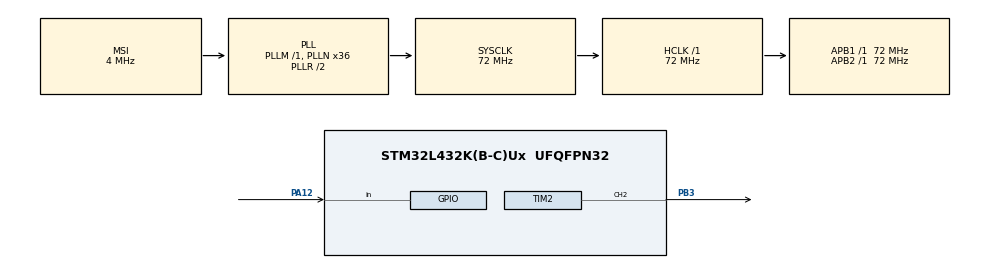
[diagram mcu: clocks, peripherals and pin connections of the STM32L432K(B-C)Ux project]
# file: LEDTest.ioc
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Mcu.Family=STM32L4
Mcu.Name=STM32L432K(B-C)Ux
Mcu.Package=UFQFPN32
NVIC.PriorityGroup=NVIC_PRIORITYGROUP_4
PA0.GPIO_Label=MCO [High speed clock in]
PA0.Mode=HSE-External-Clock-Source-for-LittleOrca
PA0.Signal=RCC_CK_IN
PA12.Signal=GPIO_Input
PA13\ (JTMS-SWDIO).GPIO_Label=SWDIO
PA13\ (JTMS-SWDIO).Mode=Serial_Wire
PA13\ (JTMS-SWDIO).Signal=SYS_JTMS-SWDIO
PA14\ (JTCK-SWCLK).GPIO_Label=SWCLK
PA14\ (JTCK-SWCLK).Mode=Serial_Wire
PA14\ (JTCK-SWCLK).Signal=SYS_JTCK-SWCLK
PA15\ (JTDI).Signal=USART2_RX
PA2.GPIO_Label=VCP_TX
PA2.Signal=USART2_TX
PB3\ (JTDO-TRACESWO).Signal=S_TIM2_CH2
PC14-OSC32_IN\ (PC14).Mode=LSE-External-Oscillator
PC14-OSC32_IN\ (PC14).Signal=RCC_OSC32_IN
PC15-OSC32_OUT\ (PC15).Mode=LSE-External-Oscillator
PC15-OSC32_OUT\ (PC15).Signal=RCC_OSC32_OUT
ProjectManager.HeapSize=0x200
ProjectManager.StackSize=0x400
ProjectManager.TargetToolchain=STM32CubeIDE
RCC.AHBFreq_Value=72000000
RCC.APB1Freq_Value=72000000
RCC.APB1TimFreq_Value=72000000
RCC.APB2Freq_Value=72000000
RCC.APB2TimFreq_Value=72000000
RCC.CortexFreq_Value=72000000
RCC.HCLKFreq_Value=72000000
RCC.HSE_VALUE=8000000
RCC.HSI16_VALUE=16000000
RCC.HSI48_VALUE=48000000
RCC.HSI_VALUE=16000000
RCC.MSI_VALUE=4000000
RCC.PLLMUL=RCC_PLLMUL_4
RCC.PLLN=36
RCC.SYSCLKFreq_VALUE=72000000
RCC.SYSCLKSource=RCC_SYSCLKSOURCE_PLLCLK
RCC.VCOOutputFreq_Value=144000000
SH.S_TIM2_CH2.0=TIM2_CH2,PWM Generation2 CH2
TIM2.AutoReloadPreload=TIM_AUTORELOAD_PRELOAD_ENABLE
TIM2.Channel-PWM\ Generation2\ CH2=TIM_CHANNEL_2
TIM2.Period=65535
VP_TIM2_VS_ClockSourceINT.Mode=Internal
board=NUCLEO-L432KC

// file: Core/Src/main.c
/* USER CODE BEGIN Header */
/**
  ******************************************************************************
  * @file           : main.c
  * @brief          : Main program body
  ******************************************************************************
  * @attention
  *
  * Copyright (c) 2022 STMicroelectronics.
  * All rights reserved.
  *
  * This software is licensed under terms that can be found in the LICENSE file
  * in the root directory of this software component.
  * If no LICENSE file comes with this software, it is provided AS-IS.
  *
  ******************************************************************************
  */
/* USER CODE END Header */
#include "main.h"

 TIM_HandleTypeDef htim2;

void SystemClock_Config(void);
static void MX_GPIO_Init(void);
static void MX_TIM2_Init(void);

int main(void)
{
  /* USER CODE BEGIN 1 */
	int32_t CH2_DC = 0;
	int32_t delay = 1;

  /* USER CODE END 1 */

  /* MCU Configuration--------------------------------------------------------*/

  /* Reset of all peripherals, Initializes the Flash interface and the Systick. */
  HAL_Init();

  /* Configure the system clock */
  SystemClock_Config();

  /* Initialize all configured peripherals */
  MX_GPIO_Init();
  MX_TIM2_Init();
  /* USER CODE BEGIN 2 */

  HAL_TIM_PWM_Start(&htim2, TIM_CHANNEL_2); //Starts PWM

  /* USER CODE END 2 */

  /* Infinite loop */
  /* USER CODE BEGIN WHILE */
  while (1)
  {
	  while(CH2_DC < 65535){
		  TIM2->CCR2 = CH2_DC;
		  CH2_DC += 70;
		  HAL_Delay(delay);
	  }
	  while(CH2_DC > 0){
		  TIM2->CCR2 = CH2_DC;
		  CH2_DC -= 70;
		  //HAL_GPIO_WritePin(GPIOB, GPIO_PIN_3, 0);
		  HAL_Delay(delay);
	  }
    /* USER CODE END WHILE */

  }
}

void SystemClock_Config(void)
{
  RCC_OscInitTypeDef RCC_OscInitStruct = {0};
  RCC_ClkInitTypeDef RCC_ClkInitStruct = {0};

  /** Configure the main internal regulator output voltage
  */
  if (HAL_PWREx_ControlVoltageScaling(PWR_REGULATOR_VOLTAGE_SCALE1) != HAL_OK)
  {
    Error_Handler();
  }

  /** Configure LSE Drive Capability
  */
  HAL_PWR_EnableBkUpAccess();
  __HAL_RCC_LSEDRIVE_CONFIG(RCC_LSEDRIVE_LOW);

  /** Initializes the RCC Oscillators according to the specified parameters
  * in the RCC_OscInitTypeDef structure.
  */
  RCC_OscInitStruct.OscillatorType = RCC_OSCILLATORTYPE_LSE|RCC_OSCILLATORTYPE_MSI;
  RCC_OscInitStruct.LSEState = RCC_LSE_ON;
  RCC_OscInitStruct.MSIState = RCC_MSI_ON;
  RCC_OscInitStruct.MSICalibrationValue = 0;
  RCC_OscInitStruct.MSIClockRange = RCC_MSIRANGE_6;
  RCC_OscInitStruct.PLL.PLLState = RCC_PLL_ON;
  RCC_OscInitStruct.PLL.PLLSource = RCC_PLLSOURCE_MSI;
  RCC_OscInitStruct.PLL.PLLM = 1;
  RCC_OscInitStruct.PLL.PLLN = 36;
  RCC_OscInitStruct.PLL.PLLP = RCC_PLLP_DIV7;
  RCC_OscInitStruct.PLL.PLLQ = RCC_PLLQ_DIV2;
  RCC_OscInitStruct.PLL.PLLR = RCC_PLLR_DIV2;
  if (HAL_RCC_OscConfig(&RCC_OscInitStruct) != HAL_OK)
  {
    Error_Handler();
  }

  /** Initializes the CPU, AHB and APB buses clocks
  */
  RCC_ClkInitStruct.ClockType = RCC_CLOCKTYPE_HCLK|RCC_CLOCKTYPE_SYSCLK
                              |RCC_CLOCKTYPE_PCLK1|RCC_CLOCKTYPE_PCLK2;
  RCC_ClkInitStruct.SYSCLKSource = RCC_SYSCLKSOURCE_PLLCLK;
  RCC_ClkInitStruct.AHBCLKDivider = RCC_SYSCLK_DIV1;
  RCC_ClkInitStruct.APB1CLKDivider = RCC_HCLK_DIV1;
  RCC_ClkInitStruct.APB2CLKDivider = RCC_HCLK_DIV1;

  if (HAL_RCC_ClockConfig(&RCC_ClkInitStruct, FLASH_LATENCY_4) != HAL_OK)
  {
    Error_Handler();
  }

  /** Enable MSI Auto calibration
  */
  HAL_RCCEx_EnableMSIPLLMode();
}

static void MX_TIM2_Init(void)
{

  TIM_ClockConfigTypeDef sClockSourceConfig = {0};
  TIM_MasterConfigTypeDef sMasterConfig = {0};
  TIM_OC_InitTypeDef sConfigOC = {0};

  htim2.Instance = TIM2;
  htim2.Init.Prescaler = 0;
  htim2.Init.CounterMode = TIM_COUNTERMODE_UP;
  htim2.Init.Period = 65535;
  htim2.Init.ClockDivision = TIM_CLOCKDIVISION_DIV1;
  htim2.Init.AutoReloadPreload = TIM_AUTORELOAD_PRELOAD_ENABLE;
  if (HAL_TIM_Base_Init(&htim2) != HAL_OK)
  {
    Error_Handler();
  }
  sClockSourceConfig.ClockSource = TIM_CLOCKSOURCE_INTERNAL;
  if (HAL_TIM_ConfigClockSource(&htim2, &sClockSourceConfig) != HAL_OK)
  {
    Error_Handler();
  }
  if (HAL_TIM_PWM_Init(&htim2) != HAL_OK)
  {
    Error_Handler();
  }
  sMasterConfig.MasterOutputTrigger = TIM_TRGO_RESET;
  sMasterConfig.MasterSlaveMode = TIM_MASTERSLAVEMODE_DISABLE;
  if (HAL_TIMEx_MasterConfigSynchronization(&htim2, &sMasterConfig) != HAL_OK)
  {
    Error_Handler();
  }
  sConfigOC.OCMode = TIM_OCMODE_PWM1;
  sConfigOC.Pulse = 0;
  sConfigOC.OCPolarity = TIM_OCPOLARITY_HIGH;
  sConfigOC.OCFastMode = TIM_OCFAST_DISABLE;
  if (HAL_TIM_PWM_ConfigChannel(&htim2, &sConfigOC, TIM_CHANNEL_2) != HAL_OK)
  {
    Error_Handler();
  }
  HAL_TIM_MspPostInit(&htim2);

}

static void MX_GPIO_Init(void)
{
  GPIO_InitTypeDef GPIO_InitStruct = {0};

  /* GPIO Ports Clock Enable */
  __HAL_RCC_GPIOC_CLK_ENABLE();
  __HAL_RCC_GPIOA_CLK_ENABLE();
  __HAL_RCC_GPIOB_CLK_ENABLE();

  /*Configure GPIO pin : VCP_TX_Pin */
  GPIO_InitStruct.Pin = VCP_TX_Pin;
  GPIO_InitStruct.Mode = GPIO_MODE_AF_PP;
  GPIO_InitStruct.Pull = GPIO_NOPULL;
  GPIO_InitStruct.Speed = GPIO_SPEED_FREQ_VERY_HIGH;
  GPIO_InitStruct.Alternate = GPIO_AF7_USART2;
  HAL_GPIO_Init(VCP_TX_GPIO_Port, &GPIO_InitStruct);

  /*Configure GPIO pin : PA12 */
  GPIO_InitStruct.Pin = GPIO_PIN_12;
  GPIO_InitStruct.Mode = GPIO_MODE_INPUT;
  GPIO_InitStruct.Pull = GPIO_NOPULL;
  HAL_GPIO_Init(GPIOA, &GPIO_InitStruct);

  /*Configure GPIO pin : PA15 */
  GPIO_InitStruct.Pin = GPIO_PIN_15;
  GPIO_InitStruct.Mode = GPIO_MODE_AF_PP;
  GPIO_InitStruct.Pull = GPIO_NOPULL;
  GPIO_InitStruct.Speed = GPIO_SPEED_FREQ_VERY_HIGH;
  GPIO_InitStruct.Alternate = GPIO_AF3_USART2;
  HAL_GPIO_Init(GPIOA, &GPIO_InitStruct);

}

void Error_Handler(void)
{
  __disable_irq();
  while (1)
  {
  }
}
